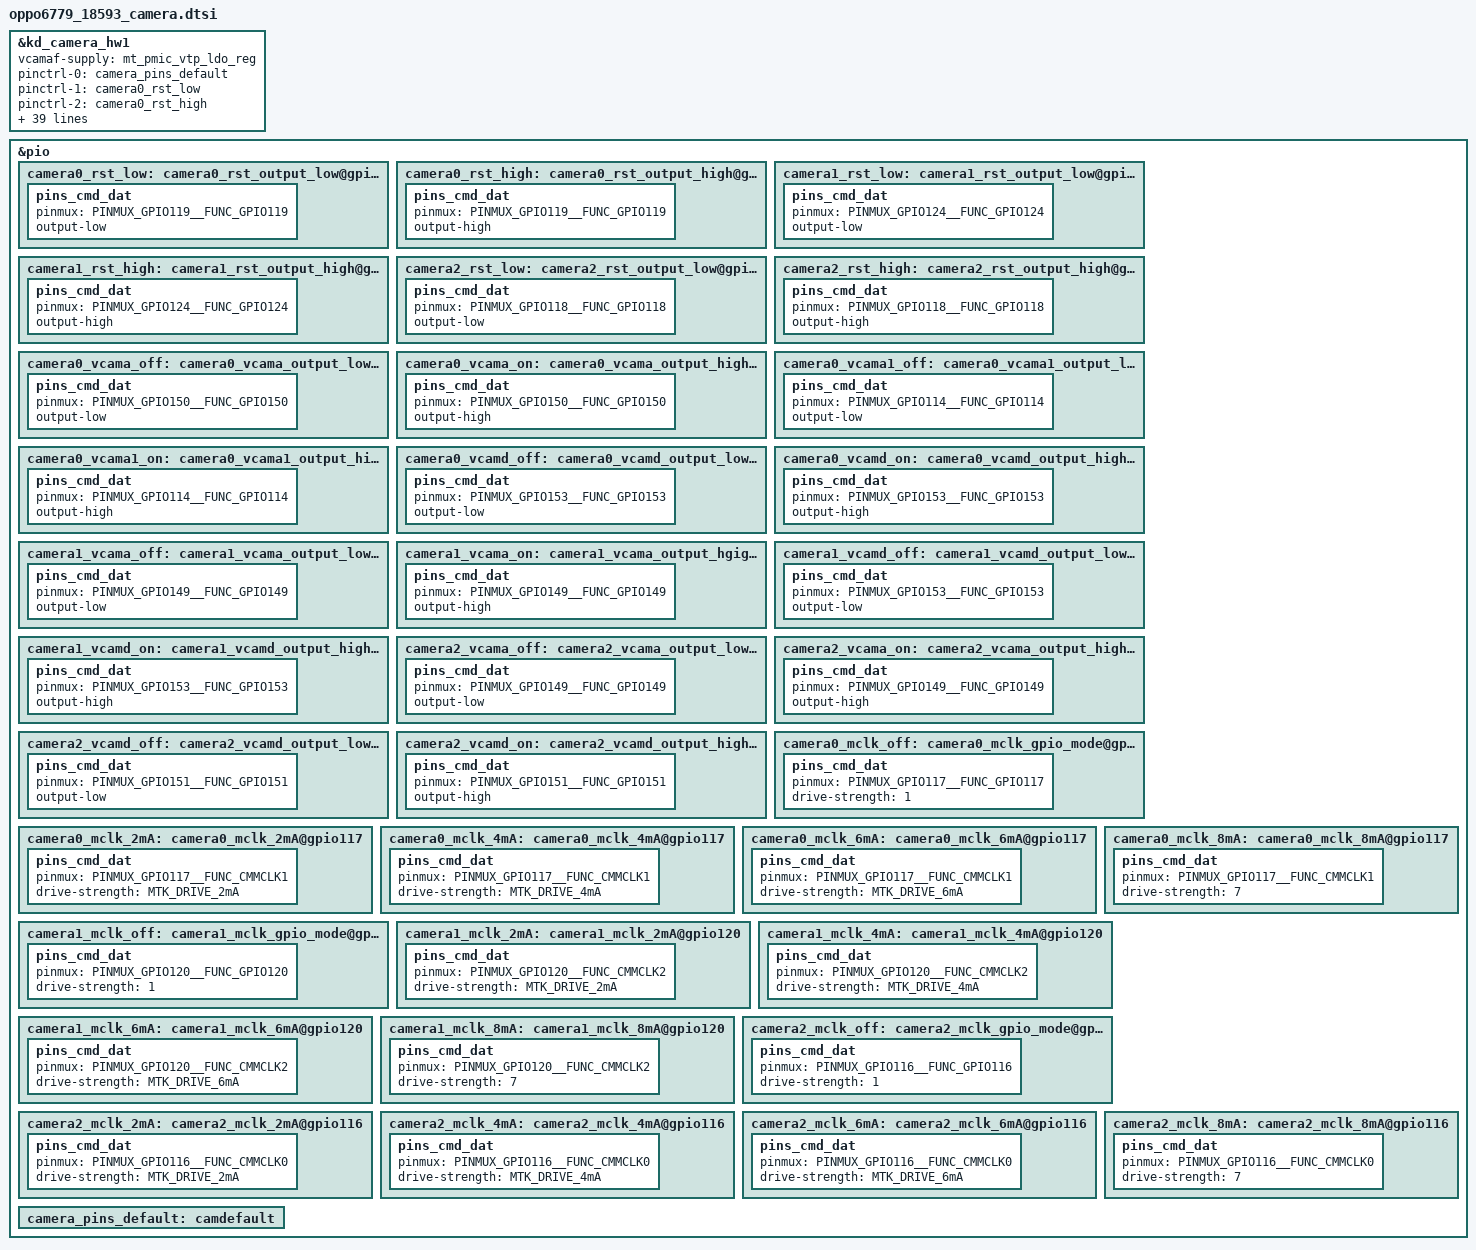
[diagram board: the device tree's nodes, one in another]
/*
 * Copyright (c) 2017 MediaTek Inc.
 *
 * This program is free software; you can redistribute it and/or modify
 * it under the terms of the GNU General Public License version 2 as
 * published by the Free Software Foundation.
 *
 * This program is distributed in the hope that it will be useful,
 * but WITHOUT ANY WARRANTY; without even the implied warranty of
 * MERCHANTABILITY or FITNESS FOR A PARTICULAR PURPOSE.  See the
 * GNU General Public License for more details.
 */


/* CAMERA GPIO standardization */
&kd_camera_hw1 {
     vcamaf-supply = <&mt_pmic_vtp_ldo_reg>;
     status = "okay";
};

&pio {
	camera0_rst_low: camera0_rst_output_low@gpio119 {
		pins_cmd_dat {
			pinmux = <PINMUX_GPIO119__FUNC_GPIO119>;
			output-low;
		};
	};
	camera0_rst_high: camera0_rst_output_high@gpio119 {
		pins_cmd_dat {
			pinmux = <PINMUX_GPIO119__FUNC_GPIO119>;
			output-high;
		};
	};
	camera1_rst_low: camera1_rst_output_low@gpio124 {
		pins_cmd_dat {
			pinmux = <PINMUX_GPIO124__FUNC_GPIO124>;
			output-low;
		};
	};
	camera1_rst_high: camera1_rst_output_high@gpio124 {
		pins_cmd_dat {
			pinmux = <PINMUX_GPIO124__FUNC_GPIO124>;
			output-high;
		};
	};
	camera2_rst_low: camera2_rst_output_low@gpio118 {
		pins_cmd_dat {
			pinmux = <PINMUX_GPIO118__FUNC_GPIO118>;
			output-low;
		};
	};
	camera2_rst_high: camera2_rst_output_high@gpio118 {
		pins_cmd_dat {
			pinmux = <PINMUX_GPIO118__FUNC_GPIO118>;
			output-high;
		};
	};
	camera0_vcama_off: camera0_vcama_output_low@gpio150 {
		pins_cmd_dat {
			pinmux = <PINMUX_GPIO150__FUNC_GPIO150>;
			output-low;
		};
	};
	camera0_vcama_on: camera0_vcama_output_high@gpio150 {
		pins_cmd_dat {
			pinmux = <PINMUX_GPIO150__FUNC_GPIO150>;
			output-high;
		};
	};
	camera0_vcama1_off: camera0_vcama1_output_low@gpio114 {
		pins_cmd_dat {
			pinmux = <PINMUX_GPIO114__FUNC_GPIO114>;
			output-low;
		};
	};
	camera0_vcama1_on: camera0_vcama1_output_high@gpio114 {
		pins_cmd_dat {
			pinmux = <PINMUX_GPIO114__FUNC_GPIO114>;
			output-high;
		};
	};
	camera0_vcamd_off: camera0_vcamd_output_low@gpio153 {
		pins_cmd_dat {
			pinmux = <PINMUX_GPIO153__FUNC_GPIO153>;
			output-low;
		};
	};
	camera0_vcamd_on: camera0_vcamd_output_high@gpio153 {
		pins_cmd_dat {
			pinmux = <PINMUX_GPIO153__FUNC_GPIO153>;
			output-high;
		};
	};
	camera1_vcama_off: camera1_vcama_output_low@gpio149 {
		pins_cmd_dat {
			pinmux = <PINMUX_GPIO149__FUNC_GPIO149>;
			output-low;
		};
	};
	camera1_vcama_on: camera1_vcama_output_hgigh@gpio149 {
		pins_cmd_dat {
			pinmux = <PINMUX_GPIO149__FUNC_GPIO149>;
			output-high;
		};
	};
	camera1_vcamd_off: camera1_vcamd_output_low@gpio153 {
		pins_cmd_dat {
			pinmux = <PINMUX_GPIO153__FUNC_GPIO153>;
			output-low;
		};
	};
	camera1_vcamd_on: camera1_vcamd_output_high@gpio153 {
		pins_cmd_dat {
			pinmux = <PINMUX_GPIO153__FUNC_GPIO153>;
			output-high;
		};
	};
	camera2_vcama_off: camera2_vcama_output_low@gpio149 {
		pins_cmd_dat {
			pinmux = <PINMUX_GPIO149__FUNC_GPIO149>;
			output-low;
		};
	};
	camera2_vcama_on: camera2_vcama_output_high@gpio149 {
		pins_cmd_dat {
			pinmux = <PINMUX_GPIO149__FUNC_GPIO149>;
			output-high;
		};
	};
	camera2_vcamd_off: camera2_vcamd_output_low@gpio151 {
		pins_cmd_dat {
			pinmux = <PINMUX_GPIO151__FUNC_GPIO151>;
			output-low;
		};
	};
	camera2_vcamd_on: camera2_vcamd_output_high@gpio151 {
		pins_cmd_dat {
			pinmux = <PINMUX_GPIO151__FUNC_GPIO151>;
			output-high;
		};
	};
	camera0_mclk_off: camera0_mclk_gpio_mode@gpio117 {
		pins_cmd_dat {
			pinmux = <PINMUX_GPIO117__FUNC_GPIO117>;
			drive-strength = <1>;
		};
	};
	camera0_mclk_2mA: camera0_mclk_2mA@gpio117 {
		pins_cmd_dat {
			pinmux = <PINMUX_GPIO117__FUNC_CMMCLK1>;
			drive-strength = <MTK_DRIVE_2mA>;
		};
	};
	camera0_mclk_4mA: camera0_mclk_4mA@gpio117 {
		pins_cmd_dat {
			pinmux = <PINMUX_GPIO117__FUNC_CMMCLK1>;
			drive-strength = <MTK_DRIVE_4mA>;
		};
	};
	camera0_mclk_6mA: camera0_mclk_6mA@gpio117 {
		pins_cmd_dat {
			pinmux = <PINMUX_GPIO117__FUNC_CMMCLK1>;
			drive-strength = <MTK_DRIVE_6mA>;
		};
	};
	camera0_mclk_8mA: camera0_mclk_8mA@gpio117 {
		pins_cmd_dat {
			pinmux = <PINMUX_GPIO117__FUNC_CMMCLK1>;
			drive-strength = <7>;
		};
	};
	camera1_mclk_off: camera1_mclk_gpio_mode@gpio120 {
		pins_cmd_dat {
			pinmux = <PINMUX_GPIO120__FUNC_GPIO120>;
			drive-strength = <1>;
		};
	};
	camera1_mclk_2mA: camera1_mclk_2mA@gpio120 {
		pins_cmd_dat {
			pinmux = <PINMUX_GPIO120__FUNC_CMMCLK2>;
			drive-strength = <MTK_DRIVE_2mA>;
		};
	};
	camera1_mclk_4mA: camera1_mclk_4mA@gpio120 {
		pins_cmd_dat {
			pinmux = <PINMUX_GPIO120__FUNC_CMMCLK2>;
			drive-strength = <MTK_DRIVE_4mA>;
		};
	};
	camera1_mclk_6mA: camera1_mclk_6mA@gpio120 {
		pins_cmd_dat {
			pinmux = <PINMUX_GPIO120__FUNC_CMMCLK2>;
			drive-strength = <MTK_DRIVE_6mA>;
		};
	};
	camera1_mclk_8mA: camera1_mclk_8mA@gpio120 {
		pins_cmd_dat {
			pinmux = <PINMUX_GPIO120__FUNC_CMMCLK2>;
			drive-strength = <7>;
		};
	};
	camera2_mclk_off: camera2_mclk_gpio_mode@gpio116 {
		pins_cmd_dat {
			pinmux = <PINMUX_GPIO116__FUNC_GPIO116>;
			drive-strength = <1>;
		};
	};
	camera2_mclk_2mA: camera2_mclk_2mA@gpio116 {
		pins_cmd_dat {
			pinmux = <PINMUX_GPIO116__FUNC_CMMCLK0>;
			drive-strength = <MTK_DRIVE_2mA>;
		};
	};
	camera2_mclk_4mA: camera2_mclk_4mA@gpio116 {
		pins_cmd_dat {
			pinmux = <PINMUX_GPIO116__FUNC_CMMCLK0>;
			drive-strength = <MTK_DRIVE_4mA>;
		};
	};
	camera2_mclk_6mA: camera2_mclk_6mA@gpio116 {
		pins_cmd_dat {
			pinmux = <PINMUX_GPIO116__FUNC_CMMCLK0>;
			drive-strength = <MTK_DRIVE_6mA>;
		};
	};
	camera2_mclk_8mA: camera2_mclk_8mA@gpio116 {
		pins_cmd_dat {
			pinmux = <PINMUX_GPIO116__FUNC_CMMCLK0>;
			drive-strength = <7>;
		};
	};

	camera_pins_default: camdefault {
	};
};
&kd_camera_hw1 {
	pinctrl-names = "default",
			"cam0_rst0", "cam0_rst1",
			"cam1_rst0", "cam1_rst1",
			"cam2_rst0", "cam2_rst1",
			"cam0_ldo_vcama_0", "cam0_ldo_vcama_1",
			"cam0_ldo_vcama1_0", "cam0_ldo_vcama1_1",
			"cam0_ldo_vcamd_0", "cam0_ldo_vcamd_1",
			"cam1_ldo_vcama_0", "cam1_ldo_vcama_1",
			"cam1_ldo_vcamd_0", "cam1_ldo_vcamd_1",
			"cam2_ldo_vcama_0", "cam2_ldo_vcama_1",
			"cam2_ldo_vcamd_0", "cam2_ldo_vcamd_1",
			"cam0_mclk_off",
			"cam0_mclk_2mA", "cam0_mclk_4mA",
			"cam0_mclk_6mA", "cam0_mclk_8mA",
			"cam1_mclk_off",
			"cam1_mclk_2mA", "cam1_mclk_4mA",
			"cam1_mclk_6mA", "cam1_mclk_8mA",
			"cam2_mclk_off",
			"cam2_mclk_2mA", "cam2_mclk_4mA",
			"cam2_mclk_6mA", "cam2_mclk_8mA";
	pinctrl-0 = <&camera_pins_default>;
	pinctrl-1 = <&camera0_rst_low>;
	pinctrl-2 = <&camera0_rst_high>;
	pinctrl-3 = <&camera1_rst_low>;
	pinctrl-4 = <&camera1_rst_high>;
	pinctrl-5 = <&camera2_rst_low>;
	pinctrl-6 = <&camera2_rst_high>;
	pinctrl-7 = <&camera0_vcama_off>;
	pinctrl-8 = <&camera0_vcama_on>;
	pinctrl-9 = <&camera0_vcama1_off>;
	pinctrl-10 = <&camera0_vcama1_on>;
	pinctrl-11 = <&camera0_vcamd_off>;
	pinctrl-12 = <&camera0_vcamd_on>;
	pinctrl-13 = <&camera1_vcama_off>;
	pinctrl-14 = <&camera1_vcama_on>;
	pinctrl-15 = <&camera1_vcamd_off>;
	pinctrl-16 = <&camera1_vcamd_on>;
	pinctrl-17 = <&camera2_vcama_off>;
	pinctrl-18 = <&camera2_vcama_on>;
	pinctrl-19 = <&camera2_vcamd_off>;
	pinctrl-20 = <&camera2_vcamd_on>;
	pinctrl-21 = <&camera0_mclk_off>;
	pinctrl-22 = <&camera0_mclk_2mA>;
	pinctrl-23 = <&camera0_mclk_4mA>;
	pinctrl-24 = <&camera0_mclk_6mA>;
	pinctrl-25 = <&camera0_mclk_8mA>;
	pinctrl-26 = <&camera1_mclk_off>;
	pinctrl-27 = <&camera1_mclk_2mA>;
	pinctrl-28 = <&camera1_mclk_4mA>;
	pinctrl-29 = <&camera1_mclk_6mA>;
	pinctrl-30 = <&camera1_mclk_8mA>;
	pinctrl-31 = <&camera2_mclk_off>;
	pinctrl-32 = <&camera2_mclk_2mA>;
	pinctrl-33 = <&camera2_mclk_4mA>;
	pinctrl-34 = <&camera2_mclk_6mA>;
	pinctrl-35 = <&camera2_mclk_8mA>;

        cam0_vcamio-supply = <&mt_pmic_vcamio_ldo_reg>;
	cam1_vcamio-supply = <&mt_pmic_vcamio_ldo_reg>;
	cam2_vcamio-supply = <&mt_pmic_vcamio_ldo_reg>;

        cam0_enable_sensor = "imx586p2q_mipi_raw";
	cam1_enable_sensor = "s5kgd1sp_mipi_raw";
	cam2_enable_sensor = "gc5035_mipi_raw";

	status = "okay";
};
/* CAMERA GPIO end */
